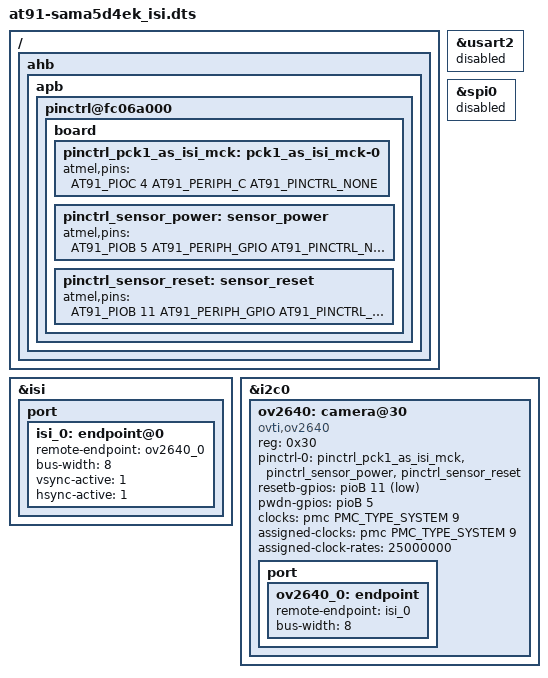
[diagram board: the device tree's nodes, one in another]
/*
 * at91-sama5d4ek_isi.dts - Device Tree file for SAMA5D4 Evaluation Kit
 *                          with ov264x sensor
 *
 *  Copyright (C) 2016 Atmel,
 *                2016 Cyrille Pitchen <cyrille.pitchen@atmel.com>
 *
 * This file is dual-licensed: you can use it either under the terms
 * of the GPL or the X11 license, at your option. Note that this dual
 * licensing only applies to this file, and not this project as a
 * whole.
 *
 *  a) This file is free software; you can redistribute it and/or
 *     modify it under the terms of the GNU General Public License as
 *     published by the Free Software Foundation; either version 2 of the
 *     License, or (at your option) any later version.
 *
 *     This file is distributed in the hope that it will be useful,
 *     but WITHOUT ANY WARRANTY; without even the implied warranty of
 *     MERCHANTABILITY or FITNESS FOR A PARTICULAR PURPOSE.  See the
 *     GNU General Public License for more details.
 *
 * Or, alternatively,
 *
 *  b) Permission is hereby granted, free of charge, to any person
 *     obtaining a copy of this software and associated documentation
 *     files (the "Software"), to deal in the Software without
 *     restriction, including without limitation the rights to use,
 *     copy, modify, merge, publish, distribute, sublicense, and/or
 *     sell copies of the Software, and to permit persons to whom the
 *     Software is furnished to do so, subject to the following
 *     conditions:
 *
 *     The above copyright notice and this permission notice shall be
 *     included in all copies or substantial portions of the Software.
 *
 *     THE SOFTWARE IS PROVIDED "AS IS", WITHOUT WARRANTY OF ANY KIND,
 *     EXPRESS OR IMPLIED, INCLUDING BUT NOT LIMITED TO THE WARRANTIES
 *     OF MERCHANTABILITY, FITNESS FOR A PARTICULAR PURPOSE AND
 *     NONINFRINGEMENT. IN NO EVENT SHALL THE AUTHORS OR COPYRIGHT
 *     HOLDERS BE LIABLE FOR ANY CLAIM, DAMAGES OR OTHER LIABILITY,
 *     WHETHER IN AN ACTION OF CONTRACT, TORT OR OTHERWISE, ARISING
 *     FROM, OUT OF OR IN CONNECTION WITH THE SOFTWARE OR THE USE OR
 *     OTHER DEALINGS IN THE SOFTWARE.
 */
#include "at91-sama5d4ek.dts"

/ {
	ahb {
		apb {
			pinctrl@fc06a000 {
				board {
					pinctrl_pck1_as_isi_mck: pck1_as_isi_mck-0 {
						atmel,pins =
							<AT91_PIOC  4 AT91_PERIPH_C AT91_PINCTRL_NONE>; /* PC4 periph C ISI_MCK */
					};

					pinctrl_sensor_power: sensor_power {
						atmel,pins =
							<AT91_PIOB  5 AT91_PERIPH_GPIO AT91_PINCTRL_NONE>; /* PB5 gpio */
					};

					pinctrl_sensor_reset: sensor_reset {
						atmel,pins =
							<AT91_PIOB 11 AT91_PERIPH_GPIO AT91_PINCTRL_NONE>; /* PB11 gpio */
					};
				};
			};
		};
	};
};

&usart2 {
	status = "disabled";
};

&spi0 {
	status = "disabled";
};

&isi {
	status = "okay";

	port {
		isi_0: endpoint@0 {
			remote-endpoint = <&ov2640_0>;
			bus-width = <8>;
			vsync-active = <1>;
			hsync-active = <1>;
		};
	};
};

&i2c0 {
	ov2640: camera@30 {
		compatible = "ovti,ov2640";
		reg = <0x30>;
		pinctrl-names = "default";
		pinctrl-0 = <&pinctrl_pck1_as_isi_mck &pinctrl_sensor_power &pinctrl_sensor_reset>;
		resetb-gpios = <&pioB 11 GPIO_ACTIVE_LOW>;
		pwdn-gpios = <&pioB 5 GPIO_ACTIVE_HIGH>;
		/* use pck1 for the master clock of ov2640 */
		clocks = <&pmc PMC_TYPE_SYSTEM 9>;
		clock-names = "xvclk";
		assigned-clocks = <&pmc PMC_TYPE_SYSTEM 9>;
		assigned-clock-rates = <25000000>;

		port {
			ov2640_0: endpoint {
				remote-endpoint = <&isi_0>;
				bus-width = <8>;
			};
		};
	};
};
